# pt_reva register map
Registers are 32-bit, read-write, no defined reset value unless marked. A register's access mark holds for its fields unless they carry their own. Offsets are from the block's base; lines under a group give offsets from that group; [hi:lo] are bit positions; {n}, {i} and the like mark numbered series; 'fields as' and 'values as' point back to an identical list; <NAME> marks a mode.

## Memory map
0x4003C020 PT size 0x10 — Pulse Train

## PT — Pulse Train
Base 0x4003C020
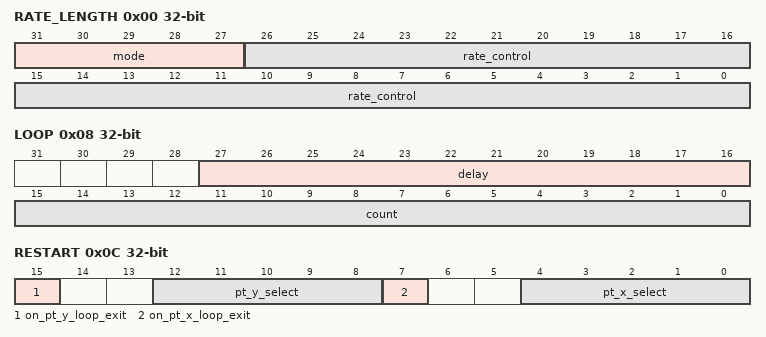
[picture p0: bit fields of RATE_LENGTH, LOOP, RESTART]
0x00 RATE_LENGTH — Pulse Train Configuration
  [31:27] mode — Pulse Train Output Mode/Train Length
    0=32_BIT (Pulse train, 32 bit pattern.); 1=SQUARE_WAVE (Square wave mode.); {v}={v}_BIT (Pulse train, {v} bit pattern.) (v=2..31)
  [26:0] rate_control — Pulse Train Enable and Rate Control. Set to 0 to disable the Pulse Train.
0x04 TRAIN — Write the repeating bit pattern that is shifted out, LSB first, when configured in Pulse Train mode. See PT_RATE_LENGTH.mode for setting the length.
0x08 LOOP — Pulse Train Loop Count
  [27:16] delay — Delay between loops of the Pulse Train in PT Peripheral Clock cycles
  [15:0] count — Number of loops for this pulse train to repeat.
0x0C RESTART — Pulse Train Auto-Restart Configuration.
  [15] on_pt_y_loop_exit — Enable Auto-Restart on PT Y Loop Exit
  [12:8] pt_y_select — Auto-Restart PT Y Select
  [7] on_pt_x_loop_exit — Enable Auto-Restart on PT X Loop Exit
  [4:0] pt_x_select — Auto-Restart PT X Select
